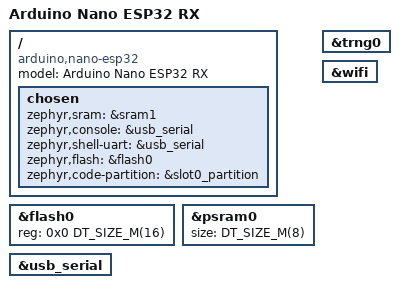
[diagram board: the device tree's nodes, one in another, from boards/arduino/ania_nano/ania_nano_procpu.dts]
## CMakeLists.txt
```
cmake_minimum_required(VERSION 3.20.0)
list(APPEND BOARD_ROOT ${CMAKE_CURRENT_SOURCE_DIR})
find_package(Zephyr REQUIRED HINTS $ENV{ZEPHYR_BASE})
project(ania_link)
target_sources(app PRIVATE src/main.c src/spi_link.c src/fast_decode.c)
set_source_files_properties(src/fast_decode.c PROPERTIES COMPILE_OPTIONS "-O3")
```

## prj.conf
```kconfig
CONFIG_ESP_SIMPLE_BOOT=y
CONFIG_NETWORKING=y
CONFIG_WIFI=y
CONFIG_ESP32_WIFI_STA_POWER_SAVE_NONE=y
CONFIG_NET_IPV6=n
CONFIG_NET_IPV4=y
CONFIG_NET_PKT_RX_COUNT=1
CONFIG_NET_PKT_TX_COUNT=1
CONFIG_NET_BUF_RX_COUNT=2
CONFIG_NET_BUF_TX_COUNT=2
CONFIG_NET_RX_STACK_SIZE=1024
CONFIG_ESP_SDR=y
CONFIG_ESP_SDR_RFTEST=y
CONFIG_ESP_SDR_RING=y
CONFIG_ESP_SDR_RING_BOX4=y
CONFIG_ESP_SDR_RING_FIR=n
CONFIG_ESP_SDR_RX_DECIM=n
CONFIG_SMP=y
CONFIG_SCHED_CPU_MASK=y
CONFIG_SHELL=y
CONFIG_SHELL_STACK_SIZE=2560
CONFIG_SHELL_HISTORY=n
CONFIG_BASE64=y
CONFIG_CRC=y
CONFIG_LOG=y
CONFIG_LOG_BUFFER_SIZE=512
CONFIG_LOG_BACKEND_UART=n
CONFIG_MAIN_STACK_SIZE=4096
CONFIG_ISR_STACK_SIZE=1024
CONFIG_FPU=y
CONFIG_FPU_SHARING=y
CONFIG_ESPTOOLPY_FLASHSIZE_16MB=y
CONFIG_ESPTOOLPY_FLASHFREQ_80M=y
CONFIG_ESP_SPIRAM=y
CONFIG_SPIRAM_MODE_OCT=y
CONFIG_ESP_SPIRAM_HEAP_SIZE=6815744
CONFIG_ESP_SPIRAM_MEMTEST=y
CONFIG_ESP_WIFI_HEAP_SPIRAM=y
CONFIG_ESP32_WIFI_STATIC_RX_BUFFER_NUM=4
CONFIG_ESP32_WIFI_MGMT_SBUF_NUM=8
CONFIG_ESP32_WIFI_EVENT_TASK_STACK_SIZE=1024
CONFIG_NET_MGMT_EVENT_STACK_SIZE=1024
CONFIG_REBOOT=y

CONFIG_SPIRAM_SPEED_80M=y

CONFIG_ESP_SDR_TX=y
CONFIG_ESP_SDR_TX_DAC=y
CONFIG_ESP_SDR_TX_DAC_RING_SAMPLES=1024

CONFIG_ESP_SDR_TX_DAC_HIGH_RAM=y

CONFIG_SPI=y
CONFIG_SPI_ASYNC=y
CONFIG_ESP32_SPI_TARGET=y
CONFIG_GPIO=y
CONFIG_SHELL_BACKEND_SERIAL=n
CONFIG_SHELL_AUTOSTART=n

CONFIG_NET_TCP=n
CONFIG_NET_UDP=y
CONFIG_SHELL_MINIMAL=y

CONFIG_LOG_PRINTK=n
CONFIG_INIT_STACKS=y
CONFIG_THREAD_STACK_INFO=y
CONFIG_STACK_SENTINEL=y
```

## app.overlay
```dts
#include <zephyr/dt-bindings/pinctrl/esp32s3-pinctrl.h>
&pinctrl {
 ania_uart: ania_uart {
  group1 { pinmux = <UART1_RX_GPIO38>; input-enable; bias-pull-up; };
  group2 { pinmux = <UART1_TX_GPIO47>; output-enable; };
 };
};
&spi2 { status = "disabled"; };
&uart1 { status = "okay"; current-speed = <230400>; pinctrl-0 = <&ania_uart>; pinctrl-names = "default"; };
```

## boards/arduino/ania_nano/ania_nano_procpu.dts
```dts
/dts-v1/;
#include <espressif/esp32s3/esp32s3.dtsi>
#include <espressif/partitions_0x0_amp.dtsi>
/ {
 model = "Arduino Nano ESP32 RX";
 compatible = "arduino,nano-esp32";
 chosen {
 zephyr,sram = &sram1;
 zephyr,console = &usb_serial;
 zephyr,shell-uart = &usb_serial;
 zephyr,flash = &flash0;
 zephyr,code-partition = &slot0_partition;
 };
};
&flash0 { reg = <0x0 DT_SIZE_M(16)>; ranges = <0x0 0x0 DT_SIZE_M(16)>; };
&psram0 { size = <DT_SIZE_M(8)>; status = "okay"; };
&usb_serial { status = "okay"; };
&trng0 { status = "okay"; };
&wifi { status = "okay"; };
```

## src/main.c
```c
/* SPDX-License-Identifier: GPL-3.0-or-later
 * Dual-board v12 radio endpoint. Captured waveforms preserved from v11.
 * Every sample-index gap is recorded; never conceal loss.
 */
#include <stdlib.h>
#include <esp_attr.h>
#include <esp_rom_crc.h>
#include <string.h>
#include <zephyr/kernel.h>
#include <zephyr/shell/shell.h>
#include <zephyr/sys/base64.h>
#include <zephyr/sys/crc.h>
#include <zephyr/multi_heap/shared_multi_heap.h>
#include <esp_sdr/esp_sdr.h>
#include <esp_sdr/esp_sdr_ring.h>
#define MAX_PAIRS 2000000U
#define DECODE_PAIRS 80000U
static int16_t *iq;
static unsigned freq=2422;
static int ready;
extern void ania_link_quiet(int enabled);
static struct esp_sdr_ring_stats stats;
static int run_rc;
static size_t target,stored;
static unsigned bits=16,stride=1;
static uint64_t expected,first_index,gap_samples,first_sink_cycles;
static size_t first_sink_pairs;
static uint32_t gap_count,segments;
struct segment {uint64_t index;uint32_t stored,n;};
static struct segment map[16];
K_SEM_DEFINE(start,0,1);
K_SEM_DEFINE(done,0,1);
static void IRAM_ATTR __attribute__((optimize("O3"))) sink(void *user,const int16_t *i,const int16_t *q,size_t n,uint64_t index){
 if(stored>=target){esp_sdr_ring_stop();return;}
 if(stored && index!=expected){gap_count++;if(index>expected)gap_samples+=(index-expected+stride-1)/stride;}
 size_t skip=(stride-index%stride)%stride;
 if(skip>=n){expected=index+n;return;}
 size_t available=(n-skip+stride-1)/stride;
 size_t take=MIN(available,target-stored);uint64_t out_index=(index+skip)/stride;
 if(!stored){first_index=out_index;first_sink_cycles=k_cycle_get_64();first_sink_pairs=n;}
 int8_t *dest=(int8_t*)iq+stored*2;
 for(size_t k=0;k<take;k++){size_t j=skip+k*stride;dest[2*k]=(int8_t)(i[j]>>6);dest[2*k+1]=(int8_t)(q[j]>>6);}
 if(segments && out_index==map[segments-1].index+map[segments-1].n){map[segments-1].n+=take;}
 else if(segments<ARRAY_SIZE(map)){map[segments++]=(struct segment){out_index,stored,take};}
 else {esp_sdr_ring_stop();return;}
 stored+=take;expected=index+n;
 if(stored>=target)esp_sdr_ring_stop();
}
static void worker(void *a,void *b,void *c){
 for(;;){
  k_sem_take(&start,K_FOREVER);
  struct esp_sdr_ring_cfg cfg={.decim=4,.shift_fs4=true,.subsample=true,.sink=sink,.unit_pairs=12288};
  run_rc=esp_sdr_ring_run(&cfg,&stats);
  k_sem_give(&done);
 }
}
K_THREAD_DEFINE(worker_id,2560,worker,NULL,NULL,NULL,K_PRIO_COOP(1),0,SYS_FOREVER_MS);
static int status(const struct shell *s,size_t argc,char **argv){
 shell_print(s,"ANIA_RING ready=%d version=13 lo_mhz=%u fs=4000000 max_pairs=%u mode=RX_TX_MANUAL capture_variant=14 modes_variant=15 release_variant=18 menu_probe_variant=19 uart_link_revision=22 rx_revision=25 sop_errors_max=12 passive_capture_ms=500",ready,freq,MAX_PAIRS);return 0;
}
static int acquire(unsigned ms,unsigned sample_bits,unsigned sample_stride){
 bits=sample_bits;stride=sample_stride;
 if(!ready || bits!=8 || stride!=1 || ms<1 || ms>500 || (uint64_t)ms*(4000/stride)>MAX_PAIRS)return -EINVAL;
 target=ms*(4000/stride);stored=0;expected=0;gap_samples=0;gap_count=0;segments=0;first_index=0;first_sink_cycles=0;first_sink_pairs=0;
 k_sem_give(&start);k_sem_take(&done,K_FOREVER);return run_rc;
}
static int dump_record(const struct shell *s){
 shell_print(s,"RING lo_mhz=%u apparent_center_mhz=%u fs=%u requested=%u stored=%u rc=%d status=%u lost_pairs=%u abandoned=%u elapsed_us=%llu gaps=%u gap_samples=%llu first_index=%llu segments=%u crc32=%u bits=%u scale=%u",freq,freq+4,4000000/stride,(unsigned)target,(unsigned)stored,run_rc,stats.status,stats.lost_pairs,stats.abandoned,stats.elapsed_us,gap_count,gap_samples,first_index,segments,crc32_ieee((uint8_t*)iq,stored*(bits/4)),bits,bits==16?16:1);
 for(unsigned j=0;j<segments;j++)shell_print(s,"M %llu %u %u",map[j].index,map[j].stored,map[j].n);
 const uint8_t *p=(uint8_t*)iq;
 for(size_t off=0;off<stored*(bits/4);off+=192){char out[257];size_t len;size_t n=MIN((size_t)192,stored*(bits/4)-off);int rc=base64_encode(out,sizeof(out),&len,p+off,n);if(rc)return rc;out[len]=0;shell_print(s,"d %s",out);}
 shell_print(s,"RING_END");return 0;
}
/* Fixed captured command waveforms. No transmission at boot or during check. */
#include <esp_sdr/esp_sdr_tx.h>
#include "waveforms.h"
#include "mode_waveforms.h"
#include "power_waveforms.h"
static int64_t power_next_ms;
#include "fast_decode.h"
extern uint32_t __esp_sdr_bank0_start[];
ESP_SDR_HIGH_BUF_DEFINE(uint32_t, tx_tail, [5000], 16);
static size_t tx_count;
static int tx_checked;
static int64_t wave_verified_until;
static float *decode_disc,*decode_chips;
static void stage_wave(const uint32_t *src,size_t n){
 tx_count=n;memcpy(__esp_sdr_bank0_start,src,MIN(n,16384U)*4);
 if(n>16384)memcpy(tx_tail,src+16384,(n-16384)*4);
}
static void IRAM_ATTR tx_gen(void *user,uint32_t *dst,uint64_t index,uint32_t n){
 while(n){
  uint32_t take;
  if(index>=tx_count){memset(dst,0,n*4);return;}
  if(index<16384){take=MIN(n,MIN((uint64_t)16384-index,tx_count-index));memcpy(dst,__esp_sdr_bank0_start+index,take*4);}
  else{take=MIN(n,tx_count-index);memcpy(dst,tx_tail+index-16384,take*4);}
  n-=take;index+=take;dst+=take;
 }
}
static int check_wave(const struct shell *s,const uint32_t *src,size_t n,const char *name,uint32_t expected_crc){
 if(n>21384)return -EINVAL;
 stage_wave(src,n);size_t cap;uint32_t *scratch=esp_sdr_tx_loop_buf(0,&cap);if(!scratch)return -ENOMEM;
 uint32_t max_us=0;for(size_t k=0;k<n;k+=16000){size_t take=MIN((size_t)16000,n-k);unsigned key=irq_lock();uint32_t t=k_cycle_get_32();tx_gen(NULL,scratch,k,take);uint32_t dt=k_cyc_to_us_floor32(k_cycle_get_32()-t);irq_unlock(key);max_us=MAX(max_us,dt);if(memcmp(scratch,src+k,take*4))return -EIO;}
 uint32_t crc=esp_rom_crc32_le(0,(const uint8_t*)src,n*4);if(crc!=expected_crc || max_us>=300)return -EIO;
 /* CRC, generated samples and fill timing were all checked above. */
 return 0;
}
static int tx_check(const struct shell *s,size_t argc,char **argv){
 uint32_t began=k_cycle_get_32();
 if(k_uptime_get()<wave_verified_until){tx_checked=1;shell_print(s,"TX_CHECK rc=0 ready=1 no_rf=1 cached=1");return 0;}
 if(esp_rom_crc32_le(0,(const uint8_t*)"123456789",9)!=0xcbf43926){tx_checked=0;shell_print(s,"TX_CHECK rc=-5 ready=0 no_rf=1");return -EIO;}
 tx_checked=0;int rc=check_wave(s,wave_plus,ARRAY_SIZE(wave_plus),"plus",CRC_PLUS);if(!rc)rc=check_wave(s,wave_minus,ARRAY_SIZE(wave_minus),"minus",CRC_MINUS);if(!rc)rc=check_wave(s,wave_release,ARRAY_SIZE(wave_release),"release",CRC_RELEASE);if(!rc)rc=check_wave(s,wave_manual,ARRAY_SIZE(wave_manual),"manual",CRC_MANUAL);if(!rc)rc=check_wave(s,wave_automatic,ARRAY_SIZE(wave_automatic),"automatic",CRC_AUTOMATIC);if(!rc)rc=check_wave(s,wave_manual_release,ARRAY_SIZE(wave_manual_release),"manual_release",CRC_MANUAL_RELEASE);if(!rc)rc=check_wave(s,wave_automatic_release,ARRAY_SIZE(wave_automatic_release),"automatic_release",CRC_AUTOMATIC_RELEASE);if(!rc)rc=check_wave(s,wave_power,ARRAY_SIZE(wave_power),"power",CRC_POWER);if(!rc)rc=check_wave(s,wave_power_release,ARRAY_SIZE(wave_power_release),"power_release",CRC_POWER_RELEASE);tx_checked=rc==0;wave_verified_until=rc?0:k_uptime_get()+60000;shell_print(s,"TX_CHECK rc=%d ready=%d no_rf=1 checked_waves=9 elapsed_us=%u",rc,tx_checked,k_cyc_to_us_floor32(k_cycle_get_32()-began));return rc;
}
static int tx_one(const struct shell *s,const uint32_t *src,size_t n,const char *name){
 stage_wave(src,n);ania_link_quiet(1);int rc=esp_sdr_tx_dac_play_gen(tx_gen,NULL,n);ania_link_quiet(0);struct esp_sdr_tx_dac_stats st;esp_sdr_tx_dac_get_stats(&st);
 shell_print(s,"TX_PACKET name=%s rc=%d errors=%u restarts=%u fill_us_max=%u slack_us_min=%d elapsed_us=%u",name,rc,st.errors,st.restarts,st.fill_us_max,st.slack_us_min,st.elapsed_us);
 if(rc||st.errors||st.restarts)wave_verified_until=0;
 return rc?rc:(st.errors||st.restarts?-EIO:0);
}
static int tx_command_once(const struct shell *s,size_t argc,char **argv){
 const uint32_t *press=NULL,*release=wave_release;size_t press_n=0,release_n=ARRAY_SIZE(wave_release);const char *name=argv[0];
 if(!strcmp(name,"plus_once")){press=wave_plus;press_n=ARRAY_SIZE(wave_plus);}
 else if(!strcmp(name,"minus_once")){press=wave_minus;press_n=ARRAY_SIZE(wave_minus);}
 else if(!strcmp(name,"manual_once")){press=wave_manual;press_n=ARRAY_SIZE(wave_manual);release=wave_manual_release;release_n=ARRAY_SIZE(wave_manual_release);}
 else if(!strcmp(name,"automatic_once")){press=wave_automatic;press_n=ARRAY_SIZE(wave_automatic);release=wave_automatic_release;release_n=ARRAY_SIZE(wave_automatic_release);}
 else if(!strcmp(name,"menu_hold3s")){press=wave_manual;press_n=ARRAY_SIZE(wave_manual);release=wave_manual_release;release_n=ARRAY_SIZE(wave_manual_release);}
 else if(!strcmp(name,"menu_exit_once")){press=wave_power;press_n=ARRAY_SIZE(wave_power);release=wave_power_release;release_n=ARRAY_SIZE(wave_power_release);}
 else if(!strcmp(name,"power_hold3s")){if(k_uptime_get()<power_next_ms){shell_print(s,"POWER_REJECT cooldown_ms=%lld no_rf=1",(long long)(power_next_ms-k_uptime_get()));return -EAGAIN;}press=wave_power;press_n=ARRAY_SIZE(wave_power);release=wave_power_release;release_n=ARRAY_SIZE(wave_power_release);}
 else return -EINVAL;
 unsigned gain=argc>1?strtoul(argv[1],0,10):0;if(gain>12)return -EINVAL;
 if(!ready || !tx_checked)return -EACCES;
 tx_checked=0;
 if(!strcmp(name,"power_hold3s"))power_next_ms=k_uptime_get()+60000;
 /* Let the adjacent Wi-Fi bridge finish TCP acknowledgement before RF. */
 k_sleep(K_MSEC(30));
 int rc=esp_sdr_set_freq(2480);if(!rc)freq=2480;if(!rc)rc=esp_sdr_tx_set_gain(gain);
 if(rc){shell_print(s,"TX_PREFLIGHT rc=%d no_rf=1",rc);return rc;}
 unsigned packets=0;int64_t hold_start=k_uptime_get();
 if(!strcmp(name,"power_hold3s")||!strcmp(name,"menu_hold3s")){
  /* Experimental hold: fixed captured packet every 64 ms, for at most 3 s. */
  for(unsigned i=0;i<47;i++){
   int64_t wait=hold_start+(int64_t)i*64-k_uptime_get();if(wait>0)k_sleep(K_MSEC(wait));
   if(k_uptime_get()-hold_start>=3000)break;
   rc=tx_one(s,press,press_n,name);packets++;if(rc)break;
  }
  int64_t wait=hold_start+3000-k_uptime_get();if(!rc&&wait>0)k_sleep(K_MSEC(wait));
  shell_print(s,!strcmp(name,"menu_hold3s")?"MENU_HOLD packets=%u elapsed_ms=%lld planned_ms=3000 cadence_ms=64 rc=%d":"POWER_HOLD packets=%u elapsed_ms=%lld planned_ms=3000 cadence_ms=64 rc=%d",packets,(long long)(k_uptime_get()-hold_start),rc);
 }else{if(!rc)rc=tx_one(s,press,press_n,name);k_sleep(K_MSEC(100));}
 /* Release is attempted even if any press waveform failed. */
 int release_rc=tx_one(s,release,release_n,"release");
 shell_print(s,"TX_DONE press_rc=%d release_rc=%d release_packets=1 gain_index=%u freq_mhz=2480",rc,release_rc,gain);
 return rc?rc:release_rc;
}
static int dump_fast(const struct shell *s){
 struct fast_frame frames[8];uint64_t start_cycles=k_cycle_get_64();
 bool continuous=stored==target&&!gap_count&&!stats.lost_pairs&&!run_rc&&segments==1;
 int count=continuous?fast_decode((const int8_t*)iq,stored,decode_disc,decode_chips,frames,ARRAY_SIZE(frames)):0;
 size_t stack_free=0;k_thread_stack_space_get(k_current_get(),&stack_free);
 uint32_t decode_us=k_cyc_to_us_floor64(k_cycle_get_64()-start_cycles),crc=0;
 shell_print(s,"FAST requested=%u stored=%u rc=%d lost_pairs=%u gaps=%u segments=%u continuous=%u decode_us=%u stack_free=%u count=%d",(unsigned)target,(unsigned)stored,run_rc,stats.lost_pairs,gap_count,segments,continuous,decode_us,(unsigned)stack_free,count);
 if(count>0)for(int i=0;i<count;i++){
  char hex[39];for(unsigned j=0;j<frames[i].len;j++){static const char digits[]="0123456789abcdef";hex[2*j]=digits[frames[i].raw[j]>>4];hex[2*j+1]=digits[frames[i].raw[j]&15];}hex[frames[i].len*2]=0;
  crc=crc32_ieee_update(crc,frames[i].raw,frames[i].len);
  shell_print(s,"F %u %u %s",frames[i].sample,frames[i].quality,hex);
 }
 shell_print(s,"FAST_END frames_crc32=%u",crc);return count<0?-ENOBUFS:0;
}
/* Neutral poll; no temperature button. RX starts before any USB output, same LO. */
static int poll_once(const struct shell *s,size_t argc,char **argv){
 unsigned gain=argc>1?strtoul(argv[1],0,10):8;unsigned settle=argc>2?strtoul(argv[2],0,10):100;unsigned window=argc>3?strtoul(argv[3],0,10):8;
 if((window!=8 && window!=20) || gain>12 || (settle!=100 && settle!=3000) || !ready || !tx_checked)return -EACCES;
 tx_checked=0;
 /* Let the adjacent Wi-Fi bridge finish TCP acknowledgement before RF. */
 k_sleep(K_MSEC(30));
 esp_sdr_set_turnaround(settle,settle==3000);
 int rc=esp_sdr_set_freq(2480);if(!rc)freq=2480;if(!rc)rc=esp_sdr_tx_set_gain(gain);if(rc)return rc;
 stage_wave(wave_release,ARRAY_SIZE(wave_release));
 ania_link_quiet(1);
 rc=esp_sdr_tx_dac_play_gen(tx_gen,NULL,ARRAY_SIZE(wave_release));uint64_t tx_end=k_cycle_get_64();
 int rx_rc=acquire(window,8,1);
 ania_link_quiet(0);
 struct esp_sdr_tx_dac_stats st;esp_sdr_tx_dac_get_stats(&st);
 if(rc||st.errors||st.restarts)wave_verified_until=0;
 uint64_t delivery=first_sink_cycles?k_cyc_to_us_floor64(first_sink_cycles-tx_end):0;
 shell_print(s,"POLL tx_rc=%d rx_rc=%d gain=%u tx_errors=%u tx_restarts=%u first_delivery_after_tx_us=%llu first_sink_pairs=%u rx_retuned=0 settle_us=%u",rc,rx_rc,gain,st.errors,st.restarts,delivery,(unsigned)first_sink_pairs,settle);
 if(!strcmp(argv[0],"fast_poll"))dump_fast(s);else dump_record(s);return rc?rc:rx_rc;
}
static int dump_long_decoded(const struct shell *s);
static int long_poll(const struct shell *s,size_t argc,char **argv){
 if(argc!=2||strcmp(argv[1],"10")||!ready||!tx_checked)return -EINVAL;
 tx_checked=0;k_sleep(K_MSEC(30));esp_sdr_set_turnaround(100,false);
 int rc=esp_sdr_set_freq(2480);if(!rc)rc=esp_sdr_tx_set_gain(10);if(rc)return rc;freq=2480;
 stage_wave(wave_release,ARRAY_SIZE(wave_release));ania_link_quiet(1);
 rc=esp_sdr_tx_dac_play_gen(tx_gen,NULL,ARRAY_SIZE(wave_release));
 int rx_rc=acquire(500,8,1);ania_link_quiet(0);
 struct esp_sdr_tx_dac_stats st;esp_sdr_tx_dac_get_stats(&st);
 shell_print(s,"LONG_POLL tx_rc=%d rx_rc=%d tx_errors=%u tx_restarts=%u neutral=1",rc,rx_rc,st.errors,st.restarts);
 dump_long_decoded(s);return rc?rc:rx_rc;
}
SHELL_STATIC_SUBCMD_SET_CREATE(tx_cmds,
 SHELL_CMD_ARG(long_poll,NULL,"Neutral query followed by 500 ms RX",long_poll,2,0),
 SHELL_CMD_ARG(menu_hold3s,NULL,"Supervised M hold; no parameter changes",tx_command_once,1,1),
 SHELL_CMD_ARG(menu_exit_once,NULL,"Short Power for a confirmed menu only",tx_command_once,1,1),
 SHELL_CMD_ARG(power_hold3s,NULL,"Fixed 3s Power; 60s cooldown; explicit command only",tx_command_once,1,1),
 SHELL_CMD_ARG(manual_once,NULL,"One M press and release",tx_command_once,1,1),
 SHELL_CMD_ARG(automatic_once,NULL,"One A press and release",tx_command_once,1,1),
 SHELL_CMD_ARG(fast_poll,NULL,"Neutral poll decoded on ESP32",poll_once,1,3),
 SHELL_CMD_ARG(poll,NULL,"Neutral poll [gain 0..12] [settle 100|3000 us]",poll_once,1,3),
 SHELL_CMD(check,NULL,"Verify fixed waveforms and fill timing; no RF",tx_check),
 SHELL_CMD_ARG(plus_once,NULL,"One fixed + packet then release [gain 0..12]; requires check",tx_command_once,1,1),
 SHELL_CMD_ARG(minus_once,NULL,"One fixed - packet then release [gain 0..12]; requires check",tx_command_once,1,1),
 SHELL_SUBCMD_SET_END);
SHELL_CMD_REGISTER(tx,&tx_cmds,"Explicit bounded reproduction test",NULL);

/* Decode a long passive acquisition in overlapping, bounded scratch windows. */
static int dump_long_decoded(const struct shell *s){
 bool continuous=stored==target&&!gap_count&&!stats.lost_pairs&&!run_rc&&segments==1;
 shell_print(s,"LISTEN requested=%u stored=%u rc=%d lost_pairs=%u gaps=%u segments=%u continuous=%u tx_packets=0",(unsigned)target,(unsigned)stored,run_rc,stats.lost_pairs,gap_count,segments,continuous);
 uint32_t crc=0;unsigned total=0;int decode_error=0;
 if(continuous)for(size_t base=0;base<stored;base+=72000U){
  size_t n=MIN((size_t)DECODE_PAIRS,stored-base);struct fast_frame frames[8];
  int count=fast_decode((const int8_t*)iq+2*base,n,decode_disc,decode_chips,frames,ARRAY_SIZE(frames));
  if(count<0){decode_error=count;break;}
  for(int i=0;i<count;i++){
   char hex[39];static const char digits[]="0123456789abcdef";
   for(unsigned j=0;j<frames[i].len;j++){hex[2*j]=digits[frames[i].raw[j]>>4];hex[2*j+1]=digits[frames[i].raw[j]&15];}hex[frames[i].len*2]=0;
   crc=crc32_ieee_update(crc,frames[i].raw,frames[i].len);total++;
   shell_print(s,"L %u %u %s",(unsigned)base+frames[i].sample,frames[i].quality,hex);
  }
  if(base+n>=stored)break;
 }
 shell_print(s,"LISTEN_END frames_crc32=%u count=%u decode_error=%d",crc,total,decode_error);
 return continuous&&!decode_error?0:-EIO;
}

/* Passive bounded capture: no TX, no waveform check and no command replay. */
static int passive_capture(const struct shell *s,size_t argc,char **argv){
 if(argc!=2 || strcmp(argv[1],"500") || !ready)return -EINVAL;
 int rc=esp_sdr_set_freq(2480);if(rc)return rc;freq=2480;
 shell_print(s,"CAPTURE_ARMED delay_ms=2000 window_ms=500 tx_packets=0");
 /* A bounded arming delay allows a host cue; actual RX timing remains measured. */
 k_sleep(K_MSEC(2000));
 rc=acquire(500,8,1);
 shell_print(s,"PASSIVE tx_packets=0 window_ms=500 rc=%d",rc);
 int dump_rc=!strcmp(argv[0],"listen")?dump_long_decoded(s):dump_record(s);return rc?rc:dump_rc;
}
static int rx_gain_command(const struct shell *s,size_t argc,char **argv){
 if(argc!=2)return -EINVAL;
 char *end;long gain=strtol(argv[1],&end,10);
 if(*end||gain < -1||gain>89)return -EINVAL;
 int rc=esp_sdr_rx_set_gain((int)gain);
 shell_print(s,"RX_GAIN rc=%d selected=%d max=%u no_tx=1",rc,esp_sdr_rx_get_gain(),esp_sdr_rx_gain_max());return rc;
}
SHELL_STATIC_SUBCMD_SET_CREATE(rx_cmds,
 SHELL_CMD_ARG(gain,NULL,"Receive gain only",rx_gain_command,2,0),
 SHELL_CMD_ARG(listen,NULL,"Passive 500 ms decoded capture; no RF transmission",passive_capture,2,0),
 SHELL_CMD_ARG(capture,NULL,"Passive 500 ms IQ capture; no RF transmission",passive_capture,2,0),
 SHELL_CMD(status,NULL,"RX ring status",status),
 SHELL_SUBCMD_SET_END);
SHELL_CMD_REGISTER(rx,&rx_cmds,"RX-only continuous ring experiment",NULL);
int main(void){
 iq=shared_multi_heap_alloc(SMH_REG_ATTR_EXTERNAL,MAX_PAIRS*2);
 decode_disc=shared_multi_heap_alloc(SMH_REG_ATTR_EXTERNAL,DECODE_PAIRS*sizeof(float));
 decode_chips=shared_multi_heap_alloc(SMH_REG_ATTR_EXTERNAL,(DECODE_PAIRS/4+1)*sizeof(float));
 int rc=iq&&decode_disc&&decode_chips?esp_sdr_init():-ENOMEM;
 if(!rc)rc=esp_sdr_set_freq(freq);
 if(!rc)rc=esp_sdr_rx_set_lpf(ESP_SDR_RX_LPF_AUTO);
 k_thread_cpu_pin(worker_id,1);k_thread_start(worker_id);
 extern void ania_spi_start(void);extern void ania_spi_commands(void);
 ready=rc==0;ania_spi_start();printk("ANIA_RING version=13 init=%d RX_TX_MANUAL\n",rc);ania_spi_commands();return 0;
}
```

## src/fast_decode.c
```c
/* SPDX-License-Identifier: GPL-3.0-or-later
 * C port of the project's 4 Msps discriminator and CYRF hard/soft decoder.
 * No RF operations; emits only complete length-7/16 CRC-verified frames.
 */
#include "fast_decode.h"
#include <math.h>
#include <stdlib.h>
#include <string.h>
#include "fast_filter.h"
#define SOP UINT64_C(0x17ff9e213690c782)
static const uint32_t pn[4]={0x0132be6f,0x012bf1db,0x02fa5ce3,0x02f99397};
static uint32_t code(unsigned b){unsigned r=b&31;uint32_t c=pn[(b>>5)&3];if(r)c=(c>>r)|(c<<(32-r));return c^(b<128?UINT32_MAX:0);}
static uint16_t crc(const uint8_t *p,size_t n){uint16_t c=0x2828;while(n--){c^=*p++;for(int j=0;j<8;j++)c=(c>>1)^((c&1)?0xa001:0);}return c^0xffff;}
static float median(float *v,unsigned n){for(unsigned i=1;i<n;i++){float x=v[i];unsigned j=i;while(j&&v[j-1]>x){v[j]=v[j-1];j--;}v[j]=x;}return n&1?v[n/2]:(v[n/2-1]+v[n/2])*.5f;}
static int attempt(const float *v,size_t n,int polarity,int soft,struct fast_frame *frame){
 if(n<165)return 0;
 float sign=polarity?-1.f:1.f,offset=0,bound=0;
 if(soft){
  float pos[128],neg[128],absolute[128];unsigned np=0,nn=0,na=0;
  for(unsigned block=0;block<2;block++)for(unsigned j=0;j<64;j++){
   float x=sign*v[block*68+j];if((SOP>>j)&1)pos[np++]=x;else neg[nn++]=x;
  }
  offset=(median(pos,np)+median(neg,nn))*.5f;
  for(unsigned block=0;block<2;block++)for(unsigned j=0;j<64;j++)absolute[na++]=fabsf(sign*v[block*68+j]-offset);
  bound=fmaxf(2*median(absolute,na),1e-6f);
 }
 for(unsigned block=0;block<2;block++){
  unsigned errors=0;for(unsigned j=0;j<64;j++)errors+=((sign*v[block*68+j]-offset>0)!=((SOP>>j)&1));
  if(errors>12)return 0;
 }
 unsigned count=0,wanted=19;int quality=1;
 for(size_t k=133;k+32<=n&&count<wanted;k+=32){
  uint32_t hard=0;float values[32];
  for(unsigned j=0;j<32;j++){float x=sign*v[k+j]-offset;if(x>0)hard|=UINT32_C(1)<<j;values[j]=fminf(bound,fmaxf(-bound,x));}
  unsigned best=0,besterr=33,second=33;float bestscore=-INFINITY;
  for(unsigned b=0;b<256;b++){
   uint32_t c=code(b);unsigned err=__builtin_popcount(c^hard);
   if(!soft){if(err<besterr){second=besterr;besterr=err;best=b;}else if(err<second)second=err;}
   else{float score=0;for(unsigned j=0;j<32;j++)score+=((c>>j)&1)?values[j]:-values[j];if(score>bestscore){bestscore=score;best=b;}}
  }
  if(soft){besterr=__builtin_popcount(code(best)^hard);for(unsigned b=0;b<256;b++)if(b!=best){unsigned e=__builtin_popcount(code(b)^hard);if(e<second)second=e;}}
  if(besterr>3||(int)second-(int)besterr<2)quality=0;
  frame->raw[count++]=best;
  if(count==1){if(best!=7&&best!=16)return 0;wanted=best+3;}
 }
 if(count!=wanted||crc(frame->raw,count-2)!=((unsigned)frame->raw[count-2]|(unsigned)frame->raw[count-1]<<8))return 0;
 frame->len=count;frame->quality=quality;return 1;
}
int fast_decode(const int8_t *iq,size_t n,float *disc,float *chips,struct fast_frame *out,size_t cap){
 if(n<800)return 0;
 float mi=0,mq=0;for(size_t k=0;k<n;k++){mi+=iq[2*k];mq+=iq[2*k+1];}mi/=n;mq/=n;
 float prev_i=0,prev_q=0;
 for(size_t k=0;k<n;k++){
  float fi=0,fq=0;
  if(k>=64){
   /* Symmetric FIR: pair taps to halve floating-point multiplications.
    * Steady-state sum(h)=1, so remove DC once after convolution. */
   for(unsigned j=0;j<32;j++){
    fi+=fir[j]*((int)iq[2*(k-j)]+(int)iq[2*(k-64+j)]);
    fq+=fir[j]*((int)iq[2*(k-j)+1]+(int)iq[2*(k-64+j)+1]);
   }
   fi+=fir[32]*iq[2*(k-32)];fq+=fir[32]*iq[2*(k-32)+1];fi-=mi;fq-=mq;
  }else for(unsigned j=0;j<=k;j++){fi+=fir[j]*(iq[2*(k-j)]-mi);fq+=fir[j]*(iq[2*(k-j)+1]-mq);}
  if(k)disc[k-1]=atan2f(fq*prev_i-fi*prev_q,fi*prev_i+fq*prev_q);
  prev_i=fi;prev_q=fq;
 }
 unsigned count=0;
 for(unsigned phase=0;phase<4;phase++){
  size_t length=(n-1-phase)/4;
  for(size_t k=0;k<length;k++){size_t p=phase+4*k;chips[k]=(disc[p]+disc[p+1]+disc[p+2]+disc[p+3])*.25f;}
  uint64_t bits=0;for(unsigned j=0;j<64;j++)if(chips[j]>0)bits|=UINT64_C(1)<<j;
  for(size_t k=0;k+165<=length;k++){
   unsigned errors=__builtin_popcountll(bits^SOP);int polarity=errors>=52;
   if(errors<=12||polarity){
    struct fast_frame frame;
    if(attempt(chips+k,length-k,polarity,0,&frame)||attempt(chips+k,length-k,polarity,1,&frame)){
     frame.sample=phase+4*k;int duplicate=0;
     for(unsigned i=0;i<count;i++)if(out[i].len==frame.len&&!memcmp(out[i].raw,frame.raw,frame.len)&&abs((int)out[i].sample-(int)frame.sample)<12){duplicate=1;break;}
     if(!duplicate){if(count>=cap)return -1;out[count++]=frame;}
    }
   }
   bits>>=1;if(chips[k+64]>0)bits|=UINT64_C(1)<<63;
  }
 }
 return count;
}
```

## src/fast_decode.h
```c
#ifndef ANIA_FAST_DECODE_H
#define ANIA_FAST_DECODE_H
#include <stdint.h>
#include <stddef.h>
struct fast_frame { uint8_t raw[19]; uint8_t len,quality; uint32_t sample; };
/* Scratch: n floats for discriminator; ceil(n/4) floats for chips. */
int fast_decode(const int8_t *iq,size_t n,float *disc,float *chips,struct fast_frame *out,size_t cap);
#endif
```

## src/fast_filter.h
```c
/* scipy.signal.firwin(65, 650000, fs=4000000), Hamming window. */
static const float fir[65]={
7.5659823760e-04f,
1.9701248444e-04f,
-6.6632373043e-04f,
-1.0649162386e-03f,
-4.0392373619e-04f,
1.0280828132e-03f,
1.9041986011e-03f,
8.9828745957e-04f,
-1.6734815934e-03f,
-3.4230677032e-03f,
-1.8677993605e-03f,
2.5585802270e-03f,
5.7909439189e-03f,
3.5569517397e-03f,
-3.6137252032e-03f,
-9.2354338610e-03f,
-6.3126462599e-03f,
4.7499440917e-03f,
1.4137519923e-02f,
1.0707241864e-02f,
-5.8675119624e-03f,
-2.1289395630e-02f,
-1.7901037067e-02f,
6.8658066466e-03f,
3.2733054537e-02f,
3.0958020584e-02f,
-7.6534150885e-03f,
-5.5604542735e-02f,
-6.2106494969e-02f,
8.1574126882e-03f,
1.4051224900e-01f,
2.7072087016e-01f,
3.2490188033e-01f,
2.7072087016e-01f,
1.4051224900e-01f,
8.1574126882e-03f,
-6.2106494969e-02f,
-5.5604542735e-02f,
-7.6534150885e-03f,
3.0958020584e-02f,
3.2733054537e-02f,
6.8658066466e-03f,
-1.7901037067e-02f,
-2.1289395630e-02f,
-5.8675119624e-03f,
1.0707241864e-02f,
1.4137519923e-02f,
4.7499440917e-03f,
-6.3126462599e-03f,
-9.2354338610e-03f,
-3.6137252032e-03f,
3.5569517397e-03f,
5.7909439189e-03f,
2.5585802270e-03f,
-1.8677993605e-03f,
-3.4230677032e-03f,
-1.6734815934e-03f,
8.9828745957e-04f,
1.9041986011e-03f,
1.0280828132e-03f,
-4.0392373619e-04f,
-1.0649162386e-03f,
-6.6632373043e-04f,
1.9701248444e-04f,
7.5659823760e-04f
};
```

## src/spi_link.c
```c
/* SPDX-License-Identifier: GPL-3.0-or-later
 * CRC-protected stop-and-wait output. Never retry RF.
 */
#include <zephyr/kernel.h>
#include <zephyr/multi_heap/shared_multi_heap.h>
#include <zephyr/drivers/uart.h>
#include <zephyr/drivers/gpio.h>
#include <zephyr/shell/shell.h>
#include <zephyr/random/random.h>
#include "../../nano33_gateway/link_protocol.h"
static const struct device *link_uart=DEVICE_DT_GET(DT_NODELABEL(uart1));
K_SEM_DEFINE(command_ready,0,1);
K_MUTEX_DEFINE(output_lock);
enum { FIFO_SIZE=32768 };
static uint8_t *fifo;static size_t head,tail,used;
static atomic_t busy,fault,radio_quiet,uart_active;
void ania_link_quiet(int enabled){
 atomic_set(&radio_quiet,enabled);
 if(enabled)while(atomic_get(&uart_active))k_sleep(K_MSEC(1));
}
static uint32_t boot,accepted,output_seq;
static size_t queued(void){k_mutex_lock(&output_lock,K_FOREVER);size_t n=used;k_mutex_unlock(&output_lock);return n;}
static char command[LINK_DATA+1];
static uint8_t tx[LINK_SIZE],rx[LINK_SIZE],pending[LINK_DATA];static uint8_t pending_len;
static int transport_init(const struct shell_transport *t,const void *cfg,shell_transport_handler_t h,void *ctx){return 0;}
static int transport_uninit(const struct shell_transport *t){return 0;}
static int transport_enable(const struct shell_transport *t,bool block){return 0;}
static int transport_read(const struct shell_transport *t,void *data,size_t n,size_t *got){*got=0;return 0;}
static int transport_write(const struct shell_transport *t,const void *data,size_t n,size_t *sent){
 const uint8_t *p=data;*sent=0;int64_t deadline=k_uptime_get()+5000;
 while(*sent<n){
  if(atomic_get(&fault)){*sent=n;return 0;}
  k_mutex_lock(&output_lock,K_FOREVER);
  size_t take=MIN(n-*sent,FIFO_SIZE-used);
  for(size_t i=0;i<take;i++){fifo[head]=p[*sent+i];head=(head+1)%FIFO_SIZE;}used+=take;
  k_mutex_unlock(&output_lock);*sent+=take;
  if(!take){if(k_uptime_get()>deadline){atomic_set(&fault,1);*sent=n;break;}k_sleep(K_MSEC(1));}
 }
 return 0;
}
static const struct shell_transport_api api={.init=transport_init,.uninit=transport_uninit,.enable=transport_enable,.read=transport_read,.write=transport_write};
static const struct shell_transport transport={.api=&api};
SHELL_DEFINE(link_shell,"",&transport,256,0,0);
void ania_spi_commands(void){
 struct shell_backend_config_flags flags=SHELL_DEFAULT_BACKEND_CONFIG_FLAGS;
 int rc=shell_init(&link_shell,NULL,flags,false,0);
 if(!rc)rc=shell_start(&link_shell);
 if(rc){atomic_set(&fault,1);return;}
 for(;;){k_sem_take(&command_ready,K_FOREVER);shell_execute_cmd(&link_shell,command);atomic_clear(&busy);}
}

/* UART uses existing MOSI wire as RX and MISO wire as TX. A valid frame is
 * required before any request is considered. CRC resynchronizes after loss. */
static void link_worker(void *a,void *b,void *c){
 if(!device_is_ready(link_uart)){printk("UART_LINK unavailable\n");return;}
 boot=sys_rand32_get();if(!boot)boot=1;
 size_t received=0;
 printk("UART_LINK ready=1 baud=230400 RX=D11 TX=D12 no_rf=1\n");
 for(;;){
  if(atomic_get(&radio_quiet)){k_sleep(K_MSEC(1));continue;}
  uint8_t ch;
  if(uart_poll_in(link_uart,&ch)){k_sleep(K_MSEC(1));continue;}
  rx[received++]=ch;
  if(received<LINK_SIZE)continue;
  if(!lvalid(rx)){memmove(rx,rx+1,LINK_SIZE-1);received=LINK_SIZE-1;continue;}
  for(;;){
   while(atomic_get(&radio_quiet))k_sleep(K_MSEC(1));
   atomic_set(&uart_active,1);
   if(!atomic_get(&radio_quiet))break;
   atomic_clear(&uart_active);
  }
  received=0;
  if(lget(rx+4)==boot){
   if(pending_len&&lget(rx+12)==output_seq)pending_len=0;
   if(lrequest_ok(rx,boot,accepted,atomic_get(&busy)||atomic_get(&fault)||queued()||pending_len)){
    memcpy(command,rx+20,rx[3]);command[rx[3]]=0;
    accepted=lget(rx+8);atomic_set(&busy,1);k_sem_give(&command_ready);
   }
  }
  if(!pending_len){
   k_mutex_lock(&output_lock,K_FOREVER);pending_len=MIN(used,LINK_DATA);
   for(unsigned i=0;i<pending_len;i++){pending[i]=fifo[tail];tail=(tail+1)%FIFO_SIZE;}used-=pending_len;
   k_mutex_unlock(&output_lock);if(pending_len)output_seq++;
  }
  memset(tx,0,sizeof(tx));tx[3]=pending_len;lput(tx+4,boot);lput(tx+8,output_seq);lput(tx+12,accepted);
  lput(tx+16,(atomic_get(&busy)||queued()||pending_len?LINK_BUSY:0)|(atomic_get(&fault)?LINK_FAULT:0));
  memcpy(tx+20,pending,pending_len);lseal(tx);
  for(unsigned i=0;i<LINK_SIZE;i++)uart_poll_out(link_uart,tx[i]);
  /* 64 bytes at 230400 baud: allow the TX FIFO to finish before RF. */
  k_sleep(K_MSEC(3));
  atomic_clear(&uart_active);
 }
}
K_THREAD_DEFINE(link_uart_id,2560,link_worker,NULL,NULL,NULL,-1,0,SYS_FOREVER_MS);
void ania_spi_start(void){
 fifo=shared_multi_heap_alloc(SMH_REG_ATTR_EXTERNAL,FIFO_SIZE);
 if(!fifo){atomic_set(&fault,1);return;}
 k_thread_cpu_pin(link_uart_id,0);k_thread_start(link_uart_id);
}
```
